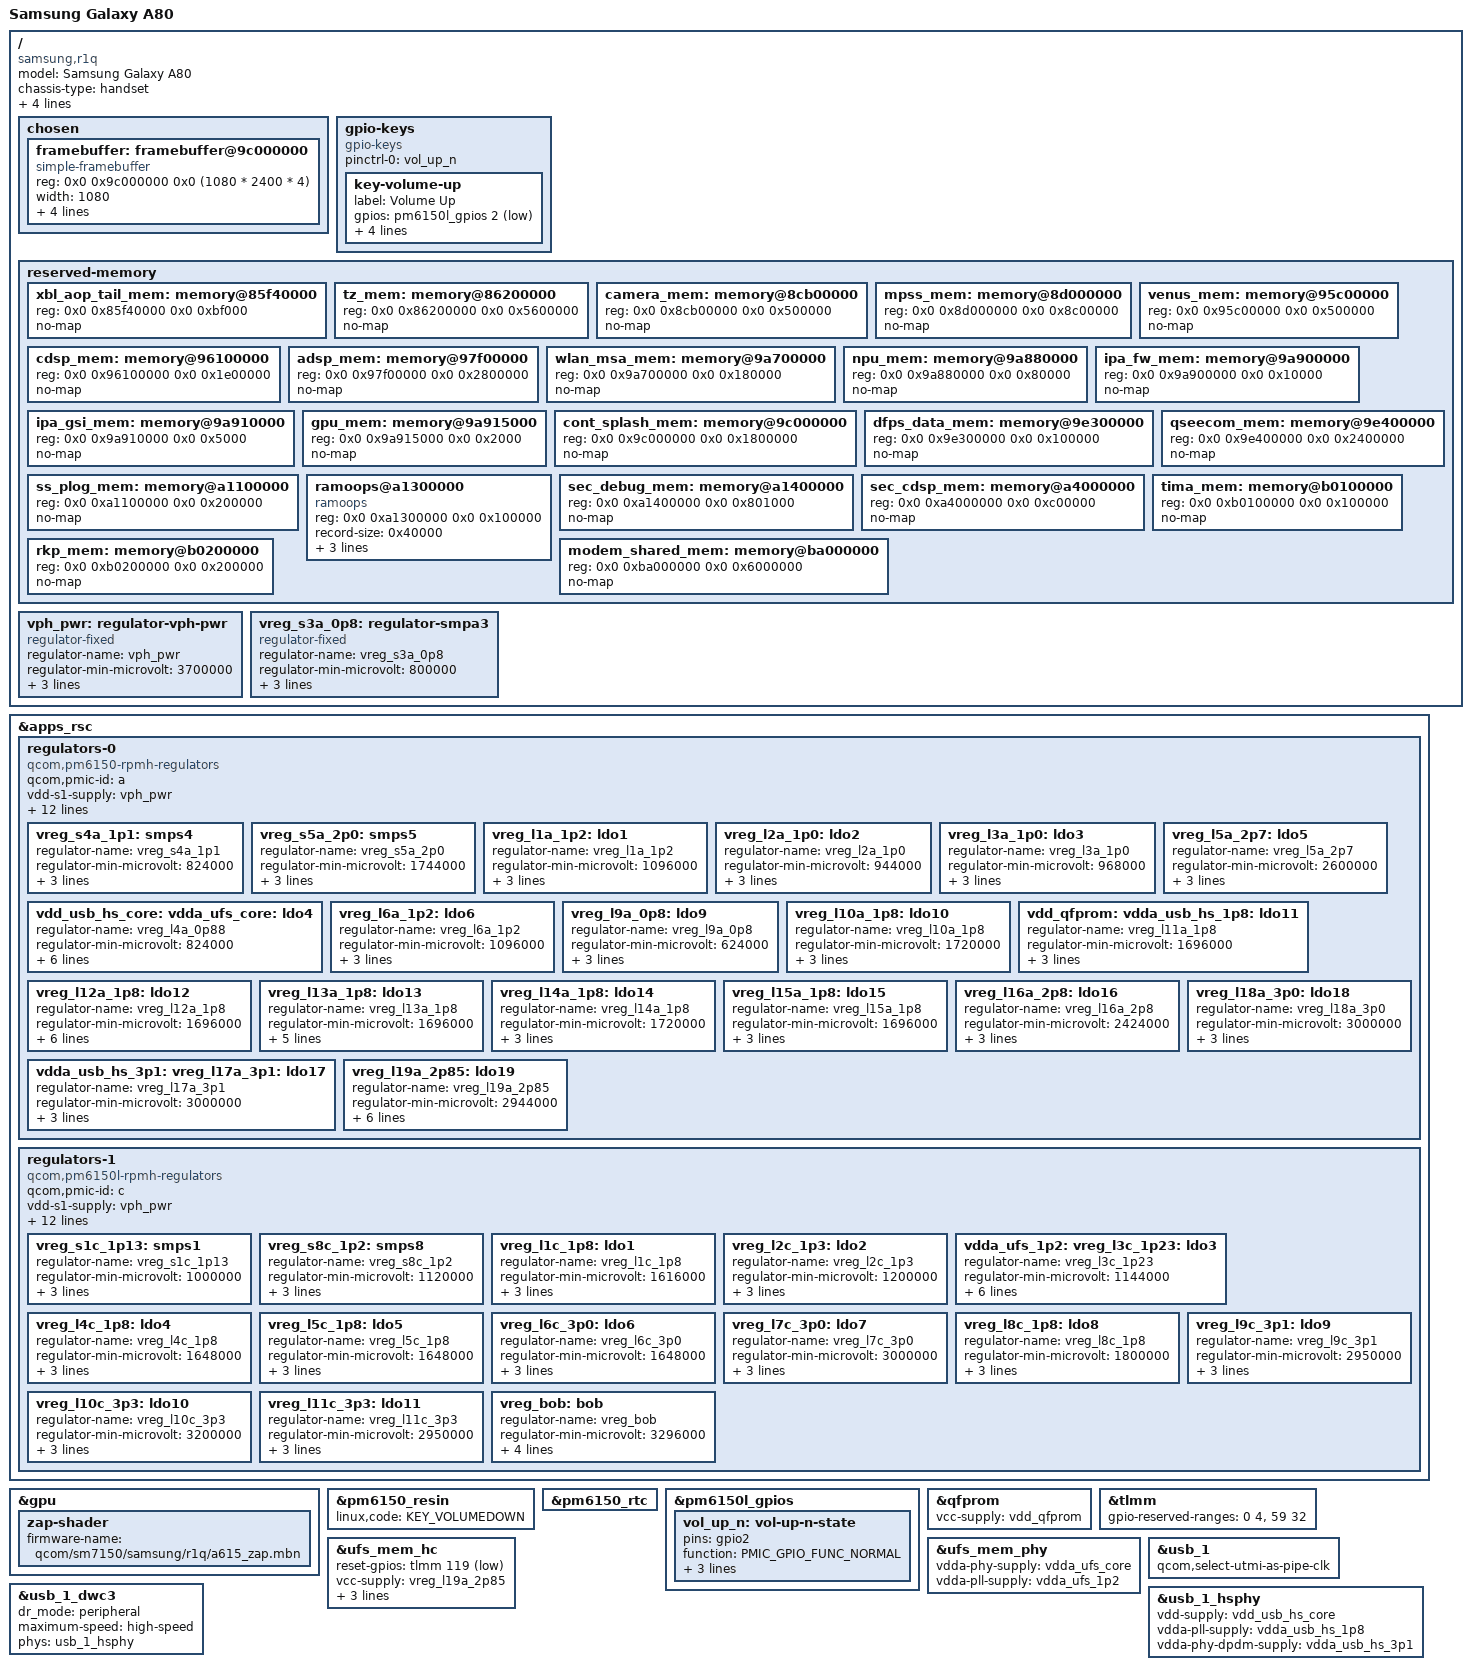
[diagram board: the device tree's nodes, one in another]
// SPDX-License-Identifier: BSD-3-Clause
/*
 * Samsung Galaxy A80 (SM-A805F, "r1q")
 *
 * Based on sm7150-google-sunfish.dts (same PM6150 + PM6150L power design).
 * Memory map, GPIOs and supplies come from the stock r1q DTB/DTBO
 * (board-id 0x22, PV2).
 *
 * Stage 1: boots with the bootloader's framebuffer, UFS, USB (peripheral,
 * high-speed only on this board), buttons and the Adreno 618 GPU.
 * Not described yet: AMS628RF05 DSI panel (S6E3FC2 based), IST40xx
 * touchscreen, Wi-Fi/BT, audio, modem, cameras, rotating camera motor.
 */

/dts-v1/;

#include <dt-bindings/firmware/qcom,scm.h>
#include <dt-bindings/gpio/gpio.h>
#include <dt-bindings/input/input.h>
#include <dt-bindings/pinctrl/qcom,pmic-gpio.h>
#include <dt-bindings/regulator/qcom,rpmh-regulator.h>

#include "sm7150.dtsi"
#include "pm6150.dtsi"
#include "pm6150l.dtsi"

/*
 * Samsung moved most firmware carveouts; drop the SoC defaults and
 * describe the r1q layout below.
 */
/delete-node/ &tz_mem;
/delete-node/ &camera_mem;
/delete-node/ &mpss_mem;
/delete-node/ &venus_mem;
/delete-node/ &cdsp_mem;
/delete-node/ &adsp_mem;
/delete-node/ &wlan_msa_mem;
/delete-node/ &npu_mem;
/delete-node/ &ipa_fw_mem;
/delete-node/ &ipa_gsi_mem;
/delete-node/ &gpu_mem;
/delete-node/ &qseecom_mem;
/delete-node/ &sec_cdsp_mem;
/delete-node/ &dfps_data_mem;

/ {
	model = "Samsung Galaxy A80";
	compatible = "samsung,r1q", "qcom,sm7150";
	chassis-type = "handset";

	/*
	 * The Samsung bootloader picks the appended DTB by these IDs; they
	 * match the base DTB in the stock and LineageOS kernels.
	 */
	qcom,msm-id = <365 0>;		/* QCOM_ID_SM7150 */
	qcom,board-id = <0 0>;
	qcom,msm-name = "SDMMAGPIE";
	qcom,pmic-name = "PM6150";

	chosen {
		#address-cells = <2>;
		#size-cells = <2>;
		ranges;

		/* Continuous splash set up by the bootloader */
		framebuffer: framebuffer@9c000000 {
			compatible = "simple-framebuffer";
			reg = <0x0 0x9c000000 0x0 (1080 * 2400 * 4)>;
			width = <1080>;
			height = <2400>;
			stride = <(1080 * 4)>;
			format = "a8r8g8b8";

			clocks = <&gcc GCC_DISP_HF_AXI_CLK>;
		};
	};

	gpio-keys {
		compatible = "gpio-keys";

		pinctrl-0 = <&vol_up_n>;
		pinctrl-names = "default";

		key-volume-up {
			label = "Volume Up";
			gpios = <&pm6150l_gpios 2 GPIO_ACTIVE_LOW>;
			linux,code = <KEY_VOLUMEUP>;
			debounce-interval = <15>;
			linux,can-disable;
			wakeup-source;
		};
	};

	reserved-memory {
		/* Stock reserves xbl_aop_mem as one 0x2ff000 block; cover the tail */
		xbl_aop_tail_mem: memory@85f40000 {
			reg = <0x0 0x85f40000 0x0 0xbf000>;
			no-map;
		};

		tz_mem: memory@86200000 {
			reg = <0x0 0x86200000 0x0 0x5600000>;
			no-map;
		};

		camera_mem: memory@8cb00000 {
			reg = <0x0 0x8cb00000 0x0 0x500000>;
			no-map;
		};

		mpss_mem: memory@8d000000 {
			reg = <0x0 0x8d000000 0x0 0x8c00000>;
			no-map;
		};

		venus_mem: memory@95c00000 {
			reg = <0x0 0x95c00000 0x0 0x500000>;
			no-map;
		};

		cdsp_mem: memory@96100000 {
			reg = <0x0 0x96100000 0x0 0x1e00000>;
			no-map;
		};

		adsp_mem: memory@97f00000 {
			reg = <0x0 0x97f00000 0x0 0x2800000>;
			no-map;
		};

		wlan_msa_mem: memory@9a700000 {
			reg = <0x0 0x9a700000 0x0 0x180000>;
			no-map;
		};

		npu_mem: memory@9a880000 {
			reg = <0x0 0x9a880000 0x0 0x80000>;
			no-map;
		};

		ipa_fw_mem: memory@9a900000 {
			reg = <0x0 0x9a900000 0x0 0x10000>;
			no-map;
		};

		ipa_gsi_mem: memory@9a910000 {
			reg = <0x0 0x9a910000 0x0 0x5000>;
			no-map;
		};

		gpu_mem: memory@9a915000 {
			reg = <0x0 0x9a915000 0x0 0x2000>;
			no-map;
		};

		cont_splash_mem: memory@9c000000 {
			reg = <0x0 0x9c000000 0x0 0x1800000>;
			no-map;
		};

		dfps_data_mem: memory@9e300000 {
			reg = <0x0 0x9e300000 0x0 0x100000>;
			no-map;
		};

		qseecom_mem: memory@9e400000 {
			reg = <0x0 0x9e400000 0x0 0x2400000>;
			no-map;
		};

		ss_plog_mem: memory@a1100000 {
			reg = <0x0 0xa1100000 0x0 0x200000>;
			no-map;
		};

		/* Same place as the stock kernel: read it back from /sys/fs/pstore */
		ramoops@a1300000 {
			compatible = "ramoops";
			reg = <0x0 0xa1300000 0x0 0x100000>;
			record-size = <0x40000>;
			console-size = <0x40000>;
			ftrace-size = <0x40000>;
			pmsg-size = <0x40000>;
		};

		sec_debug_mem: memory@a1400000 {
			reg = <0x0 0xa1400000 0x0 0x801000>;
			no-map;
		};

		sec_cdsp_mem: memory@a4000000 {
			reg = <0x0 0xa4000000 0x0 0xc00000>;
			no-map;
		};

		tima_mem: memory@b0100000 {
			reg = <0x0 0xb0100000 0x0 0x100000>;
			no-map;
		};

		rkp_mem: memory@b0200000 {
			reg = <0x0 0xb0200000 0x0 0x200000>;
			no-map;
		};

		modem_shared_mem: memory@ba000000 {
			reg = <0x0 0xba000000 0x0 0x6000000>;
			no-map;
		};
	};

	vph_pwr: regulator-vph-pwr {
		compatible = "regulator-fixed";

		regulator-name = "vph_pwr";
		regulator-min-microvolt = <3700000>;
		regulator-max-microvolt = <3700000>;

		regulator-always-on;
		regulator-boot-on;
	};

	/* S3A is really mx.lvl, listed for supply map completeness */
	vreg_s3a_0p8: regulator-smpa3 {
		compatible = "regulator-fixed";

		regulator-name = "vreg_s3a_0p8";
		regulator-min-microvolt = <800000>;
		regulator-max-microvolt = <800000>;

		regulator-always-on;
		vin-supply = <&vph_pwr>;
	};
};

&apps_rsc {
	regulators-0 {
		compatible = "qcom,pm6150-rpmh-regulators";
		qcom,pmic-id = "a";

		vdd-s1-supply = <&vph_pwr>;
		vdd-s2-supply = <&vph_pwr>;
		vdd-s3-supply = <&vph_pwr>;
		vdd-s4-supply = <&vph_pwr>;
		vdd-s5-supply = <&vph_pwr>;

		vdd-l1-supply = <&vreg_s8c_1p2>;
		vdd-l2-l3-supply = <&vreg_s4a_1p1>;
		vdd-l4-l7-l8-supply = <&vreg_s4a_1p1>;
		vdd-l5-l16-l17-l18-l19-supply = <&vreg_bob>;
		vdd-l6-supply = <&vreg_s8c_1p2>;
		vdd-l9-supply = <&vreg_s3a_0p8>;
		vdd-l10-l14-l15-supply = <&vreg_s5a_2p0>;
		vdd-l11-l12-l13-supply = <&vreg_s5a_2p0>;

		vreg_s4a_1p1: smps4 {
			regulator-name = "vreg_s4a_1p1";
			regulator-min-microvolt = <824000>;
			regulator-max-microvolt = <1120000>;
			regulator-initial-mode = <RPMH_REGULATOR_MODE_HPM>;
		};

		vreg_s5a_2p0: smps5 {
			regulator-name = "vreg_s5a_2p0";
			regulator-min-microvolt = <1744000>;
			regulator-max-microvolt = <2040000>;
			regulator-initial-mode = <RPMH_REGULATOR_MODE_HPM>;
		};

		vreg_l1a_1p2: ldo1 {
			regulator-name = "vreg_l1a_1p2";
			regulator-min-microvolt = <1096000>;
			regulator-max-microvolt = <1304000>;
			regulator-initial-mode = <RPMH_REGULATOR_MODE_HPM>;
		};

		vreg_l2a_1p0: ldo2 {
			regulator-name = "vreg_l2a_1p0";
			regulator-min-microvolt = <944000>;
			regulator-max-microvolt = <1056000>;
			regulator-initial-mode = <RPMH_REGULATOR_MODE_HPM>;
		};

		vreg_l3a_1p0: ldo3 {
			regulator-name = "vreg_l3a_1p0";
			regulator-min-microvolt = <968000>;
			regulator-max-microvolt = <1064000>;
			regulator-initial-mode = <RPMH_REGULATOR_MODE_HPM>;
		};

		vdd_usb_hs_core:
		vdda_ufs_core:
		vreg_l4a_0p88: ldo4 {
			regulator-name = "vreg_l4a_0p88";
			regulator-min-microvolt = <824000>;
			regulator-max-microvolt = <920000>;
			regulator-initial-mode = <RPMH_REGULATOR_MODE_HPM>;
			regulator-allow-set-load;
			regulator-allowed-modes = <RPMH_REGULATOR_MODE_LPM
						   RPMH_REGULATOR_MODE_HPM>;
		};

		vreg_l5a_2p7: ldo5 {
			regulator-name = "vreg_l5a_2p7";
			regulator-min-microvolt = <2600000>;
			regulator-max-microvolt = <2800000>;
			regulator-initial-mode = <RPMH_REGULATOR_MODE_HPM>;
		};

		vreg_l6a_1p2: ldo6 {
			regulator-name = "vreg_l6a_1p2";
			regulator-min-microvolt = <1096000>;
			regulator-max-microvolt = <1304000>;
			regulator-initial-mode = <RPMH_REGULATOR_MODE_HPM>;
		};

		vreg_l9a_0p8: ldo9 {
			regulator-name = "vreg_l9a_0p8";
			regulator-min-microvolt = <624000>;
			regulator-max-microvolt = <760000>;
			regulator-initial-mode = <RPMH_REGULATOR_MODE_HPM>;
		};

		vreg_l10a_1p8: ldo10 {
			regulator-name = "vreg_l10a_1p8";
			regulator-min-microvolt = <1720000>;
			regulator-max-microvolt = <1832000>;
			regulator-initial-mode = <RPMH_REGULATOR_MODE_HPM>;
		};

		vdd_qfprom:
		vdda_usb_hs_1p8:
		vreg_l11a_1p8: ldo11 {
			regulator-name = "vreg_l11a_1p8";
			regulator-min-microvolt = <1696000>;
			regulator-max-microvolt = <1984000>;
			regulator-initial-mode = <RPMH_REGULATOR_MODE_HPM>;
		};

		vreg_l12a_1p8: ldo12 {
			regulator-name = "vreg_l12a_1p8";
			regulator-min-microvolt = <1696000>;
			regulator-max-microvolt = <1952000>;
			regulator-initial-mode = <RPMH_REGULATOR_MODE_HPM>;
			regulator-allow-set-load;
			regulator-allowed-modes = <RPMH_REGULATOR_MODE_LPM
						   RPMH_REGULATOR_MODE_HPM>;
		};

		/* Panel VDDIO; keep it on so the bootloader's splash stays lit */
		vreg_l13a_1p8: ldo13 {
			regulator-name = "vreg_l13a_1p8";
			regulator-min-microvolt = <1696000>;
			regulator-max-microvolt = <1904000>;
			regulator-initial-mode = <RPMH_REGULATOR_MODE_HPM>;
			regulator-always-on;
			regulator-boot-on;
		};

		vreg_l14a_1p8: ldo14 {
			regulator-name = "vreg_l14a_1p8";
			regulator-min-microvolt = <1720000>;
			regulator-max-microvolt = <1856000>;
			regulator-initial-mode = <RPMH_REGULATOR_MODE_HPM>;
		};

		vreg_l15a_1p8: ldo15 {
			regulator-name = "vreg_l15a_1p8";
			regulator-min-microvolt = <1696000>;
			regulator-max-microvolt = <1904000>;
			regulator-initial-mode = <RPMH_REGULATOR_MODE_HPM>;
		};

		vreg_l16a_2p8: ldo16 {
			regulator-name = "vreg_l16a_2p8";
			regulator-min-microvolt = <2424000>;
			regulator-max-microvolt = <2976000>;
			regulator-initial-mode = <RPMH_REGULATOR_MODE_HPM>;
		};

		vdda_usb_hs_3p1:
		vreg_l17a_3p1: ldo17 {
			regulator-name = "vreg_l17a_3p1";
			regulator-min-microvolt = <3000000>;
			regulator-max-microvolt = <3232000>;
			regulator-initial-mode = <RPMH_REGULATOR_MODE_HPM>;
		};

		/* Touchscreen AVDD on the stock kernel */
		vreg_l18a_3p0: ldo18 {
			regulator-name = "vreg_l18a_3p0";
			regulator-min-microvolt = <3000000>;
			regulator-max-microvolt = <3000000>;
			regulator-initial-mode = <RPMH_REGULATOR_MODE_HPM>;
		};

		vreg_l19a_2p85: ldo19 {
			regulator-name = "vreg_l19a_2p85";
			regulator-min-microvolt = <2944000>;
			regulator-max-microvolt = <3304000>;
			regulator-initial-mode = <RPMH_REGULATOR_MODE_HPM>;
			regulator-allow-set-load;
			regulator-allowed-modes = <RPMH_REGULATOR_MODE_LPM
						   RPMH_REGULATOR_MODE_HPM>;
		};
	};

	regulators-1 {
		compatible = "qcom,pm6150l-rpmh-regulators";
		qcom,pmic-id = "c";

		vdd-s1-supply = <&vph_pwr>;
		vdd-s2-supply = <&vph_pwr>;
		vdd-s3-supply = <&vph_pwr>;
		vdd-s4-supply = <&vph_pwr>;
		vdd-s5-supply = <&vph_pwr>;
		vdd-s6-supply = <&vph_pwr>;
		vdd-s7-supply = <&vph_pwr>;
		vdd-s8-supply = <&vph_pwr>;

		vdd-l2-l3-supply = <&vreg_s8c_1p2>;
		vdd-l4-l5-l6-supply = <&vreg_bob>;
		vdd-l7-l11-supply = <&vreg_bob>;
		vdd-l9-l10-supply = <&vreg_bob>;

		vdd-bob-supply = <&vph_pwr>;

		vreg_s1c_1p13: smps1 {
			regulator-name = "vreg_s1c_1p13";
			regulator-min-microvolt = <1000000>;
			regulator-max-microvolt = <1200000>;
			regulator-initial-mode = <RPMH_REGULATOR_MODE_HPM>;
		};

		/* r1q limits from the stock DTB are tighter than the reference board's */
		vreg_s8c_1p2: smps8 {
			regulator-name = "vreg_s8c_1p2";
			regulator-min-microvolt = <1120000>;
			regulator-max-microvolt = <1408000>;
			regulator-initial-mode = <RPMH_REGULATOR_MODE_HPM>;
		};

		vreg_l1c_1p8: ldo1 {
			regulator-name = "vreg_l1c_1p8";
			regulator-min-microvolt = <1616000>;
			regulator-max-microvolt = <1984000>;
			regulator-initial-mode = <RPMH_REGULATOR_MODE_HPM>;
		};

		vreg_l2c_1p3: ldo2 {
			regulator-name = "vreg_l2c_1p3";
			regulator-min-microvolt = <1200000>;
			regulator-max-microvolt = <1352000>;
			regulator-initial-mode = <RPMH_REGULATOR_MODE_HPM>;
		};

		vdda_ufs_1p2:
		vreg_l3c_1p23: ldo3 {
			regulator-name = "vreg_l3c_1p23";
			regulator-min-microvolt = <1144000>;
			regulator-max-microvolt = <1256000>;
			regulator-initial-mode = <RPMH_REGULATOR_MODE_HPM>;
			regulator-allow-set-load;
			regulator-allowed-modes = <RPMH_REGULATOR_MODE_LPM
						   RPMH_REGULATOR_MODE_HPM>;
		};

		vreg_l4c_1p8: ldo4 {
			regulator-name = "vreg_l4c_1p8";
			regulator-min-microvolt = <1648000>;
			regulator-max-microvolt = <2950000>;
			regulator-initial-mode = <RPMH_REGULATOR_MODE_HPM>;
		};

		vreg_l5c_1p8: ldo5 {
			regulator-name = "vreg_l5c_1p8";
			regulator-min-microvolt = <1648000>;
			regulator-max-microvolt = <2950000>;
			regulator-initial-mode = <RPMH_REGULATOR_MODE_HPM>;
		};

		vreg_l6c_3p0: ldo6 {
			regulator-name = "vreg_l6c_3p0";
			regulator-min-microvolt = <1648000>;
			regulator-max-microvolt = <3100000>;
			regulator-initial-mode = <RPMH_REGULATOR_MODE_HPM>;
		};

		vreg_l7c_3p0: ldo7 {
			regulator-name = "vreg_l7c_3p0";
			regulator-min-microvolt = <3000000>;
			regulator-max-microvolt = <3312000>;
			regulator-initial-mode = <RPMH_REGULATOR_MODE_HPM>;
		};

		vreg_l8c_1p8: ldo8 {
			regulator-name = "vreg_l8c_1p8";
			regulator-min-microvolt = <1800000>;
			regulator-max-microvolt = <1900000>;
			regulator-initial-mode = <RPMH_REGULATOR_MODE_HPM>;
		};

		vreg_l9c_3p1: ldo9 {
			regulator-name = "vreg_l9c_3p1";
			regulator-min-microvolt = <2950000>;
			regulator-max-microvolt = <3312000>;
			regulator-initial-mode = <RPMH_REGULATOR_MODE_HPM>;
		};

		vreg_l10c_3p3: ldo10 {
			regulator-name = "vreg_l10c_3p3";
			regulator-min-microvolt = <3200000>;
			regulator-max-microvolt = <3312000>;
			regulator-initial-mode = <RPMH_REGULATOR_MODE_HPM>;
		};

		vreg_l11c_3p3: ldo11 {
			regulator-name = "vreg_l11c_3p3";
			regulator-min-microvolt = <2950000>;
			regulator-max-microvolt = <3400000>;
			regulator-initial-mode = <RPMH_REGULATOR_MODE_HPM>;
		};

		vreg_bob: bob {
			regulator-name = "vreg_bob";
			regulator-min-microvolt = <3296000>;
			regulator-max-microvolt = <3960000>;
			regulator-initial-mode = <RPMH_REGULATOR_MODE_AUTO>;
			regulator-allow-bypass;
		};
	};
};

&gpu {
	/* Samsung-signed; copied from the phone's vendor partition (see docs) */
	zap-shader {
		firmware-name = "qcom/sm7150/samsung/r1q/a615_zap.mbn";
	};
};

&pm6150_resin {
	linux,code = <KEY_VOLUMEDOWN>;
	status = "okay";
};

&pm6150_rtc {
	status = "okay";
};

&pm6150l_gpios {
	vol_up_n: vol-up-n-state {
		pins = "gpio2";
		function = PMIC_GPIO_FUNC_NORMAL;
		input-enable;
		bias-pull-up;
		power-source = <0>;
	};
};

&qfprom {
	vcc-supply = <&vdd_qfprom>;
};

&tlmm {
	/*
	 * Pins TrustZone owns on r1q; reading them (pinctrl does at probe)
	 * resets the phone. Found by bisection on the phone: 0-3 (eSE on
	 * SPI1), 59-62 (fingerprint SPI, as on the other SM7150 phones) and
	 * a pin in 63-90, kept reserved as a whole until it is narrowed down.
	 */
	gpio-reserved-ranges = <0 4>, <59 32>;
};

&ufs_mem_hc {
	reset-gpios = <&tlmm 119 GPIO_ACTIVE_LOW>;

	vcc-supply = <&vreg_l19a_2p85>;
	vcc-max-microamp = <600000>;
	vccq2-supply = <&vreg_l12a_1p8>;
	vccq2-max-microamp = <600000>;
	status = "okay";
};

&ufs_mem_phy {
	vdda-phy-supply = <&vdda_ufs_core>;
	vdda-pll-supply = <&vdda_ufs_1p2>;
	status = "okay";
};

&usb_1 {
	/* The r1q board only wires up USB 2.0 */
	qcom,select-utmi-as-pipe-clk;
	status = "okay";
};

&usb_1_dwc3 {
	/* Gadget only until the Type-C port controller is described */
	dr_mode = "peripheral";
	maximum-speed = "high-speed";
	phys = <&usb_1_hsphy>;
	phy-names = "usb2-phy";
};

&usb_1_hsphy {
	vdd-supply = <&vdd_usb_hs_core>;
	vdda-pll-supply = <&vdda_usb_hs_1p8>;
	vdda-phy-dpdm-supply = <&vdda_usb_hs_3p1>;
	status = "okay";
};
